# PIC18F45Q10 register map
Vendor: Microchip
Registers are 8-bit, read-write, reset 0x0 unless marked. A register's access mark holds for its fields unless they carry their own. Addresses are absolute, and some are shared; only a register's first bit layout is shown; [hi:lo] are bit positions; {n}, {i} and the like mark numbered series; 'fields as' and 'values as' point back to an identical list.

## SFR
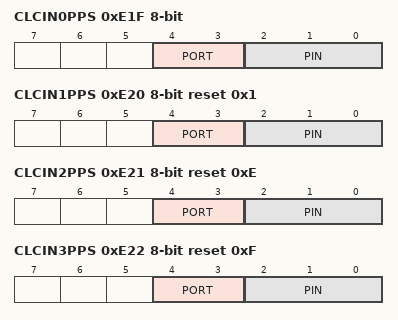
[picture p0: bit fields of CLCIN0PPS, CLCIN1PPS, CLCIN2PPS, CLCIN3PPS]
0xE1F CLCIN0PPS
  [4:3] PORT, [2:0] PIN
0xE20 CLCIN1PPS reset 0x1
  [4:3] PORT, [2:0] PIN
0xE21 CLCIN2PPS reset 0xE
  [4:3] PORT, [2:0] PIN
0xE22 CLCIN3PPS reset 0xF
  [4:3] PORT, [2:0] PIN
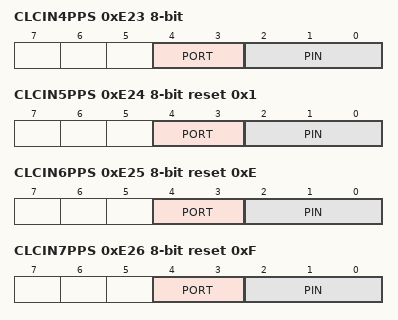
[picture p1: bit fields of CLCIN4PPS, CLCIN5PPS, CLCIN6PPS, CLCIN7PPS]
0xE23 CLCIN4PPS
  [4:3] PORT, [2:0] PIN
0xE24 CLCIN5PPS reset 0x1
  [4:3] PORT, [2:0] PIN
0xE25 CLCIN6PPS reset 0xE
  [4:3] PORT, [2:0] PIN
0xE26 CLCIN7PPS reset 0xF
  [4:3] PORT, [2:0] PIN
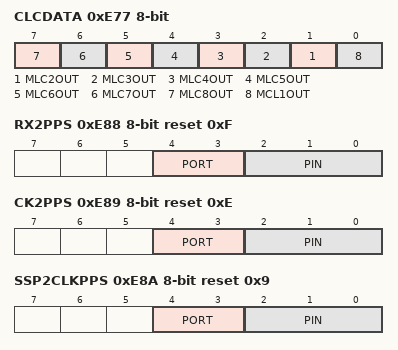
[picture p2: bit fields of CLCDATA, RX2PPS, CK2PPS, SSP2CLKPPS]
0xE77 CLCDATA reset not defined — (power-on value xxxxxxxx)
  [n-1] MLC{n}OUT (n=2..8), [0] MCL1OUT
0xE88 RX2PPS reset 0xF
  [4:3] PORT, [2:0] PIN
0xE89 CK2PPS reset 0xE
  [4:3] PORT, [2:0] PIN
0xE8A SSP2CLKPPS reset 0x9
  [4:3] PORT, [2:0] PIN
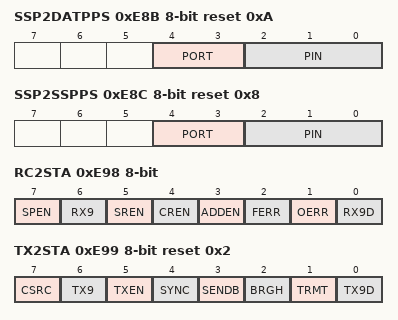
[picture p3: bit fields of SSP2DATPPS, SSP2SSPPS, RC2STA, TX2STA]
0xE8B SSP2DATPPS reset 0xA
  [4:3] PORT, [2:0] PIN
0xE8C SSP2SSPPS reset 0x8
  [4:3] PORT, [2:0] PIN
0xE94 RC2REG ro
0xE95 TX2REG
0xE96 SP2BRGL
0xE97 SP2BRGH
0xE98 RC2STA
  [7] SPEN, [6] RX9, [5] SREN, [4] CREN, [3] ADDEN, [2] FERR ro, [1] OERR ro, [0] RX9D ro
0xE99 TX2STA reset 0x2
  [7] CSRC, [6] TX9, [5] TXEN, [4] SYNC, [3] SENDB, [2] BRGH, [1] TRMT ro, [0] TX9D
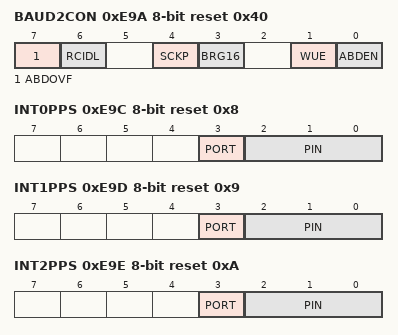
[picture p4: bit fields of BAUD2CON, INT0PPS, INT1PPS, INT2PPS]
0xE9A BAUD2CON reset 0x40
  [7] ABDOVF ro, [6] RCIDL ro, [4] SCKP, [3] BRG16, [1] WUE, [0] ABDEN
0xE9B PPSLOCK
  [0] PPSLOCKED
0xE9C INT0PPS reset 0x8
  [3] PORT, [2:0] PIN
0xE9D INT1PPS reset 0x9
  [3] PORT, [2:0] PIN
0xE9E INT2PPS reset 0xA
  [3] PORT, [2:0] PIN
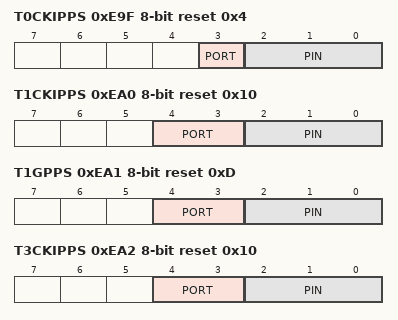
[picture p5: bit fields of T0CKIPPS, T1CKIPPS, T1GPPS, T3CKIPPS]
0xE9F T0CKIPPS reset 0x4
  [3] PORT, [2:0] PIN
0xEA0 T1CKIPPS reset 0x10
  [4:3] PORT, [2:0] PIN
0xEA1 T1GPPS reset 0xD
  [4:3] PORT, [2:0] PIN
0xEA2 T3CKIPPS reset 0x10
  [4:3] PORT, [2:0] PIN
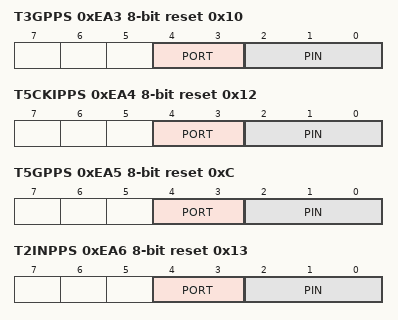
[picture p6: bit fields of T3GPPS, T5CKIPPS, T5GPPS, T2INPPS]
0xEA3 T3GPPS reset 0x10
  [4:3] PORT, [2:0] PIN
0xEA4 T5CKIPPS reset 0x12
  [4:3] PORT, [2:0] PIN
0xEA5 T5GPPS reset 0xC
  [4:3] PORT, [2:0] PIN
0xEA6 T2INPPS reset 0x13
  [4:3] PORT, [2:0] PIN
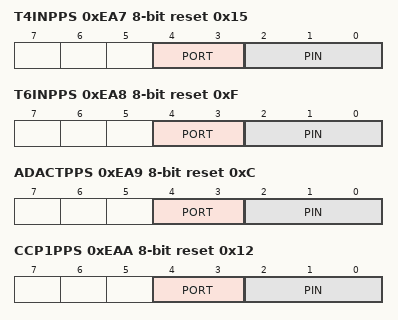
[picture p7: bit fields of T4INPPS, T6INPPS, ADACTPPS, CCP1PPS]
0xEA7 T4INPPS reset 0x15
  [4:3] PORT, [2:0] PIN
0xEA8 T6INPPS reset 0xF
  [4:3] PORT, [2:0] PIN
0xEA9 ADACTPPS reset 0xC
  [4:3] PORT, [2:0] PIN
0xEAA CCP1PPS reset 0x12
  [4:3] PORT, [2:0] PIN
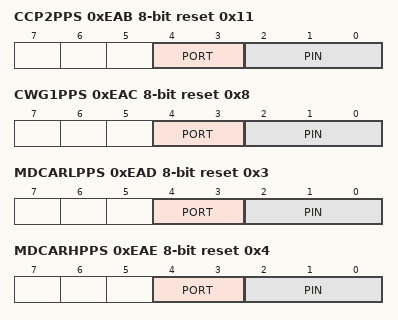
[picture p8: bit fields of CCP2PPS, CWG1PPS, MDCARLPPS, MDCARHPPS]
0xEAB CCP2PPS reset 0x11
  [4:3] PORT, [2:0] PIN
0xEAC CWG1PPS reset 0x8
  [4:3] PORT, [2:0] PIN
0xEAD MDCARLPPS reset 0x3
  [4:3] PORT, [2:0] PIN
0xEAE MDCARHPPS reset 0x4
  [4:3] PORT, [2:0] PIN
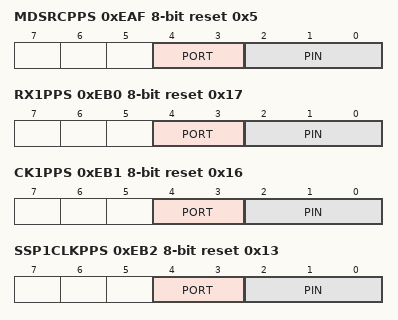
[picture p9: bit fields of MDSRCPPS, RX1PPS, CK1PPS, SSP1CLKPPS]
0xEAF MDSRCPPS reset 0x5
  [4:3] PORT, [2:0] PIN
0xEB0 RX1PPS reset 0x17
  [4:3] PORT, [2:0] PIN
0xEB1 CK1PPS reset 0x16
  [4:3] PORT, [2:0] PIN
0xEB2 SSP1CLKPPS reset 0x13
  [4:3] PORT, [2:0] PIN
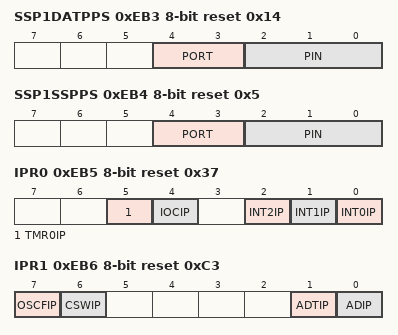
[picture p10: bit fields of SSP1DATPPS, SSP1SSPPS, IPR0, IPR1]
0xEB3 SSP1DATPPS reset 0x14
  [4:3] PORT, [2:0] PIN
0xEB4 SSP1SSPPS reset 0x5
  [4:3] PORT, [2:0] PIN
0xEB5 IPR0 reset 0x37
  [5] TMR0IP, [4] IOCIP, [2] INT2IP, [1] INT1IP, [0] INT0IP
0xEB6 IPR1 reset 0xC3
  [7] OSCFIP, [6] CSWIP, [1] ADTIP, [0] ADIP
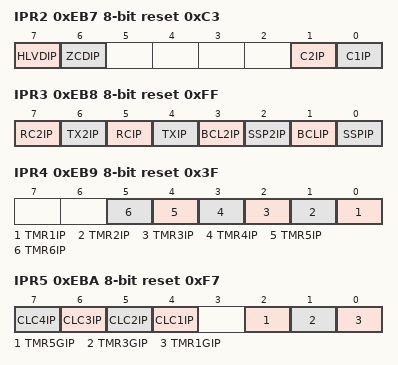
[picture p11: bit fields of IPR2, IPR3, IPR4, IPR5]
0xEB7 IPR2 reset 0xC3
  [7] HLVDIP, [6] ZCDIP, [1] C2IP, [0] C1IP
0xEB8 IPR3 reset 0xFF
  [7] RC2IP, [6] TX2IP, [5] RCIP, [4] TXIP, [3] BCL2IP, [2] SSP2IP, [1] BCLIP, [0] SSPIP
0xEB9 IPR4 reset 0x3F
  [n-1] TMR{n}IP (n=1..6)
0xEBA IPR5 reset 0xF7
  [n+3] CLC{n}IP (n=1..4), [2] TMR5GIP, [1] TMR3GIP, [0] TMR1GIP
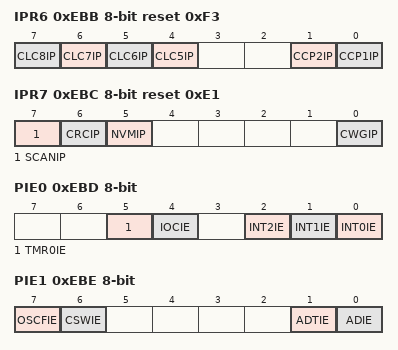
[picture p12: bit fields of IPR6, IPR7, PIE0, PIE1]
0xEBB IPR6 reset 0xF3
  [n-1] CLC{n}IP (n=5..8), [1] CCP2IP, [0] CCP1IP
0xEBC IPR7 reset 0xE1
  [7] SCANIP, [6] CRCIP, [5] NVMIP, [0] CWGIP
0xEBD PIE0
  [5] TMR0IE, [4] IOCIE, [2] INT2IE, [1] INT1IE, [0] INT0IE
0xEBE PIE1
  [7] OSCFIE, [6] CSWIE, [1] ADTIE, [0] ADIE
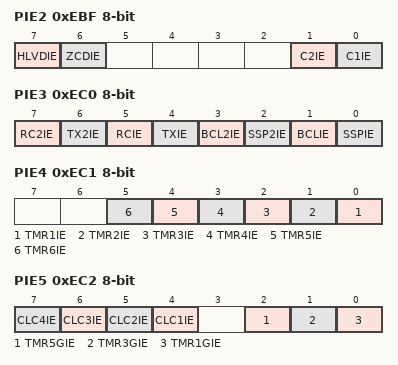
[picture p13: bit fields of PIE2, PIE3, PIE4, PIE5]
0xEBF PIE2
  [7] HLVDIE, [6] ZCDIE, [1] C2IE, [0] C1IE
0xEC0 PIE3
  [7] RC2IE, [6] TX2IE, [5] RCIE, [4] TXIE, [3] BCL2IE, [2] SSP2IE, [1] BCLIE, [0] SSPIE
0xEC1 PIE4
  [n-1] TMR{n}IE (n=1..6)
0xEC2 PIE5
  [n+3] CLC{n}IE (n=1..4), [2] TMR5GIE, [1] TMR3GIE, [0] TMR1GIE
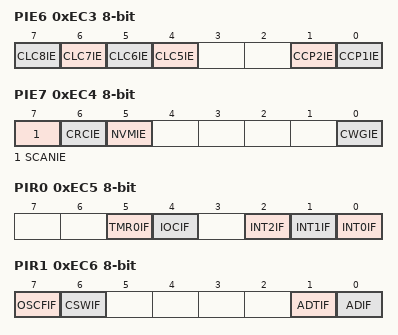
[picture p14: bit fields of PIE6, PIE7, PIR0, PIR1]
0xEC3 PIE6
  [n-1] CLC{n}IE (n=5..8), [1] CCP2IE, [0] CCP1IE
0xEC4 PIE7
  [7] SCANIE, [6] CRCIE, [5] NVMIE, [0] CWGIE
0xEC5 PIR0
  [5] TMR0IF, [4] IOCIF ro, [2] INT2IF, [1] INT1IF, [0] INT0IF
0xEC6 PIR1
  [7] OSCFIF, [6] CSWIF, [1] ADTIF, [0] ADIF
0xEC7 PIR2
  [7] HLVDIF, [6] ZCDIF, [1] C2IF, [0] C1IF
0xEC8 PIR3
  [7] RC2IF ro, [6] TX2IF ro, [5] RCIF ro, [4] TXIF ro, [3] BCL2IF, [2] SSP2IF, [1] BCLIF, [0] SSPIF
0xEC9 PIR4
  [n-1] TMR{n}IF (n=1..6)
0xECA PIR5
  [n+3] CLC{n}IF (n=1..4), [2] TMR5GIF, [1] TMR3GIF, [0] TMR1GIF
0xECB PIR6
  [n-1] CLC{n}IF (n=5..8), [1] CCP2IF, [0] CCP1IF
0xECC PIR7
  [7] SCANIF, [6] CRCIF, [5] NVMIF, [0] CWGIF
0xED2 CPUDOZE
  [7] IDLEN, [6] DOZEN, [5] ROI, [4] DOE, [2:0] DOZE
0xED3 OSCCON1 reset not defined — (power-on value -qqqqqqq)
  [6:4] NOSC, [3:0] NDIV
0xED4 OSCCON2 ro reset not defined — (power-on value -qqqqqqq)
  [6:4] COSC, [3:0] CDIV
0xED5 OSCCON3
  [7] CSWHOLD, [6] SOSCPWR, [4] ORDY ro, [3] NOSCR ro
0xED6 OSCSTAT ro reset not defined — (power-on value qqqqqq-q)
  [7] EXTOR, [6] HFOR, [5] MFOR, [4] LFOR, [3] SOR, [2] ADOR, [0] PLLR
0xED7 OSCEN
  [7] EXTOEN, [6] HFOEN, [5] MFOEN, [4] LFOEN, [3] SOSCEN, [2] ADOEN
0xED8 OSCTUNE
  [5:0] TUN
0xED9 OSCFRQ reset not defined — (power-on value ----q0q0)
  [3:0] HFFRQ
0xEDA VREGCON reset not defined — (power-on value --qq--10)
  [5:4] PMSYS ro, [1:0] VREGPM
0xEDB BORCON reset not defined — (power-on value 1------q)
  [7] SBOREN, [0] BORRDY ro
0xF38 CMOUT ro
  [1] MC2OUT, [0] MC1OUT
0xF39 CLKRCON reset 0x10
  [7] EN, [4:3] DC, [2:0] DIV
0xF3A CLKRCLK
  [2:0] CLK
0xF79 NVMADRL
0xF7A NVMADRH
0xF7B NVMADRU
  [5:0] NVMADRU
0xF7C NVMDATL
0xF7D NVMDATH
0xF7F NVMCON0 reset not defined — (power-on value 0--xx---)
  [7] NVMEN, [4] NVMERR
0xF80 NVMCON1
  [6] SECER — (can only be set)
  [5] SECWR — (can only be set)
  [4] WR — (can only be set)
  [1] SECRD — (can only be set)
  [0] RD — (can only be set)
0xF81 NVMCON2 wo
0xF82 LATA reset not defined — (power-on value xxxxxxxx)
  [n] LATA{n} (n=0..7)
0xF83 LATB reset not defined — (power-on value xxxxxxxx)
  [n] LATB{n} (n=0..7)
0xF84 LATC reset not defined — (power-on value xxxxxxxx)
  [n] LATC{n} (n=0..7)
0xF85 LATD reset not defined — (power-on value xxxxxxxx)
  [n] LATD{n} (n=0..7)
0xF86 LATE reset not defined — (power-on value -----xxx)
  [2] LATE2, [1] LATE1, [0] LATE0
0xF87 TRISA reset 0xFF
  [n] TRISA{n} (n=0..7)
0xF88 TRISB reset 0xFF
  [n] TRISB{n} (n=0..7)
0xF89 TRISC reset 0xFF
  [n] TRISC{n} (n=0..7)
0xF8A TRISD reset 0xFF
  [n] TRISD{n} (n=0..7)
0xF8B TRISE reset 0x7
  [2] TRISE2, [1] TRISE1, [0] TRISE0
0xF8C PORTA reset not defined — (power-on value xxxxxxxx)
  [n] RA{n} (n=0..7)
0xF8D PORTB reset not defined — (power-on value xxxxxxxx)
  [n] RB{n} (n=0..7)
0xF8E PORTC reset not defined — (power-on value xxxxxxxx)
  [n] RC{n} (n=0..7)
0xF8F PORTD reset not defined — (power-on value xxxxxxxx)
  [n] RD{n} (n=0..7)
0xF90 PORTE reset not defined — (power-on value ----xxxx)
  [3] RE3 ro, [2] RE2, [1] RE1, [0] RE0
0xF98 RC1REG ro
0xF99 TX1REG
0xF9A SP1BRGL
0xF9B SP1BRGH
0xF9C RC1STA
  fields as RC2STA
0xF9D TX1STA reset 0x2
  fields as TX2STA
0xF9E BAUD1CON reset 0x40
  [7] ABDOVF ro, [6] RCIDL ro, [4] SCKP, [3] BRG16, [1] WUE, [0] ABDEN
0xFAD CCPTMRS reset 0x55
  [7:6] P4TSEL, [5:4] P3TSEL, [3:2] C2TSEL, [1:0] C1TSEL
0xFD6 PCON1 reset 0x5
  [2] RVREG, [0] RCM
0xFD7 PCON0 reset not defined — (power-on value 0011110q)
  [7] STKOVF, [6] STKUNF, [5] nWDTWV, [4] nRWDT, [3] nRMCLR, [2] nRI, [1] nPOR, [0] nBOR
0xFD8 STATUS reset 0x60
  [6] nTO ro, [5] nPD ro, [4] N, [3] OV, [2] Z, [1] DC, [0] C
0xFD9 FSR2L
0xFDA FSR2H
  [3:0] FSR2H
0xFDB PLUSW2 access not given reset not defined
0xFDC PREINC2 access not given reset not defined
0xFDD POSTDEC2 access not given reset not defined
0xFDE POSTINC2 access not given reset not defined
0xFDF INDF2 access not given reset not defined — (power-on value xxxxxxxx)
0xFE0 BSR
  [3:0] BSR
0xFE1 FSR1L
0xFE2 FSR1H
  [3:0] FSR1H
0xFE3 PLUSW1 access not given reset not defined
0xFE4 PREINC1 access not given reset not defined
0xFE5 POSTDEC1 access not given reset not defined
0xFE6 POSTINC1 access not given reset not defined
0xFE7 INDF1 access not given reset not defined — (power-on value xxxxxxxx)
0xFE8 WREG reset not defined — (power-on value xxxxxxxx)
0xFE9 FSR0L
0xFEA FSR0H
  [3:0] FSR0H
0xFEB PLUSW0 access not given reset not defined
0xFEC PREINC0 access not given reset not defined
0xFED POSTDEC0 access not given reset not defined
0xFEE POSTINC0 access not given reset not defined
0xFEF INDF0 access not given reset not defined — (power-on value xxxxxxxx)
0xFF2 INTCON reset 0x7
  [7] GIE_GIEH, [6] PEIE_GIEL, [5] IPEN, [2] INT2EDG, [1] INT1EDG, [0] INT0EDG
0xFF3 PRODL reset not defined — (power-on value xxxxxxxx)
0xFF4 PRODH reset not defined — (power-on value xxxxxxxx)
0xFF5 TABLAT
0xFF6 TBLPTRL
0xFF7 TBLPTRH
0xFF8 TBLPTRU
  [5:0] TBLPTRU
0xFF9 PCL
0xFFA PCLATH
  [7:0] PCH
0xFFB PCLATU
  [4:0] PCU
0xFFC STKPTR
  [5:0] STKPTR
0xFFD TOSL reset not defined — (power-on value xxxxxxxx)
0xFFE TOSH reset not defined — (power-on value xxxxxxxx)
0xFFF TOSU reset not defined — (power-on value ---xxxxx)
  [4:0] TOSU
